# LargeDummyDevice register map
File version: 1.0
Registers are 32-bit, read-write, no defined reset value unless marked. A register's access mark holds for its fields unless they carry their own. Offsets are from the block's base; [hi:lo] are bit positions.

## PERIPHERAL_32
Base 0x4001F000
0x04 REG_1 — Register 1
  [9:5] FIELD_1, [9:5] FIELD_3, [3] FIELD_2
0x08 REG_2 — Register 2
  [28] FIELD_18, [31:27] FIELD_6, [31:27] FIELD_16, [26] FIELD_4, [26:22] FIELD_9, [23:21] FIELD_3, [24:21] FIELD_7, [22:21] FIELD_10, [24:21] FIELD_14, [16:14] FIELD_8, [15:13] FIELD_2, [13] FIELD_11, [8] FIELD_15, [8:7] FIELD_1, [7] FIELD_17, [5] FIELD_13, [6:4] FIELD_5, [2] FIELD_12
0x0C REG_3 — Register 3
  [28:26] FIELD_8, [28:24] FIELD_3, [19:15] FIELD_9, [17:14] FIELD_1, [10] FIELD_5, [10:9] FIELD_7, [7] FIELD_4, [10:6] FIELD_10, [7:4] FIELD_2, [1] FIELD_6
0x10 REG_4 — Register 4
  [33:30] FIELD_14, [32:28] FIELD_1, [29:26] FIELD_11, [27:25] FIELD_17, [25:24] FIELD_7, [27:24] FIELD_13, [25:22] FIELD_6, [17:13] FIELD_9, [14:12] FIELD_10, [12:10] FIELD_5, [10:8] FIELD_16, [7] FIELD_4, [10:7] FIELD_12, [3:2] FIELD_15, [4:0] FIELD_2, [3:0] FIELD_3, [2:0] FIELD_8
0x14 REG_5 — Register 5
  [31:27] FIELD_2, [24:21] FIELD_5, [17:13] FIELD_4, [13:10] FIELD_6, [8:7] FIELD_1, [5:1] FIELD_3
0x18 REG_6 — Register 6
  [33:31] FIELD_1, [31] FIELD_12, [30:29] FIELD_14, [29:28] FIELD_16, [27] FIELD_5, [27:26] FIELD_2, [27:25] FIELD_18, [25:21] FIELD_8, [23:21] FIELD_9, [23:20] FIELD_15, [15:14] FIELD_6, [15:11] FIELD_4, [13:10] FIELD_7, [10] FIELD_19, [10:9] FIELD_13, [10:9] FIELD_20, [8] FIELD_3, [11:8] FIELD_10, [7:6] FIELD_17, [6] FIELD_21, [7:4] FIELD_11
0x1C REG_7 — Register 7
  [31:27] FIELD_5, [18:14] FIELD_4, [14:13] FIELD_3, [13:11] FIELD_1, [12:10] FIELD_2, [8:6] FIELD_6
0x20 REG_8 — Register 8
  [31] FIELD_2, [29] FIELD_7, [26] FIELD_4, [27:24] FIELD_1, [20:16] FIELD_5, [10:8] FIELD_6, [9:6] FIELD_8, [5] FIELD_3
0x24 REG_9 — Register 9
  [29:28] FIELD_6, [30:28] FIELD_11, [31:27] FIELD_2, [27] FIELD_10, [26:25] FIELD_26, [27:24] FIELD_14, [27:24] FIELD_22, [25:23] FIELD_7, [27:23] FIELD_27, [24:21] FIELD_4, [21] FIELD_12, [24:21] FIELD_23, [22:20] FIELD_5, [24:20] FIELD_24, [23:19] FIELD_3, [23:19] FIELD_15, [20:18] FIELD_1, [12] FIELD_16, [13:12] FIELD_25, [14:10] FIELD_21, [11:8] FIELD_9, [6:5] FIELD_20, [5:3] FIELD_13, [4:2] FIELD_18, [4:2] FIELD_19, [3:0] FIELD_8, [1:0] FIELD_17
0x28 REG_10 — Register 10
  [33:31] FIELD_5, [28] FIELD_7, [28:27] FIELD_6, [26:22] FIELD_2, [21] FIELD_4, [23:20] FIELD_1, [15:12] FIELD_3
0x2C REG_11 — Register 11
  [25:22] FIELD_4, [23:20] FIELD_1, [15:14] FIELD_3, [5:1] FIELD_2
0x30 REG_12 — Register 12
  [30:29] FIELD_1, [30:26] FIELD_5, [30:26] FIELD_7, [26:23] FIELD_8, [21] FIELD_13, [22:19] FIELD_2, [22:19] FIELD_14, [14:13] FIELD_6, [15:12] FIELD_16, [9] FIELD_11, [9:5] FIELD_10, [9:5] FIELD_12, [4] FIELD_4, [5:3] FIELD_3, [3:0] FIELD_9, [2:0] FIELD_15, [3:0] FIELD_17
0x34 REG_13 — Register 13
  [35:31] FIELD_6, [33:31] FIELD_10, [30] FIELD_2, [29:27] FIELD_1, [29:26] FIELD_5, [21:20] FIELD_7, [19] FIELD_9, [21:18] FIELD_8, [20:17] FIELD_13, [16:14] FIELD_11, [13:9] FIELD_12, [8:5] FIELD_3, [3] FIELD_14, [2:1] FIELD_4
0x38 REG_14 — Register 14
  [32:31] FIELD_8, [26] FIELD_16, [27:25] FIELD_4, [29:25] FIELD_14, [25:23] FIELD_9, [21] FIELD_10, [21:20] FIELD_7, [24:20] FIELD_11, [19] FIELD_13, [18] FIELD_18, [18:16] FIELD_5, [20:16] FIELD_19, [16:14] FIELD_2, [13] FIELD_1, [11] FIELD_15, [13:9] FIELD_6, [11:9] FIELD_17, [9:8] FIELD_21, [7:6] FIELD_20, [8:5] FIELD_3, [8:4] FIELD_22, [3:0] FIELD_12
0x3C REG_15 — Register 15
  [32:31] FIELD_21, [32:29] FIELD_17, [31:28] FIELD_22, [29:28] FIELD_23, [29:27] FIELD_2, [27] FIELD_15, [20:18] FIELD_9, [19:18] FIELD_10, [17] FIELD_5, [17:16] FIELD_7, [20:16] FIELD_11, [18:16] FIELD_16, [15] FIELD_12, [14:10] FIELD_20, [11:9] FIELD_14, [8] FIELD_1, [9:7] FIELD_18, [10:7] FIELD_25, [10:6] FIELD_19, [7:5] FIELD_3, [9:5] FIELD_4, [6:5] FIELD_8, [5:4] FIELD_13, [1:0] FIELD_6, [2:0] FIELD_24, [4:0] FIELD_26
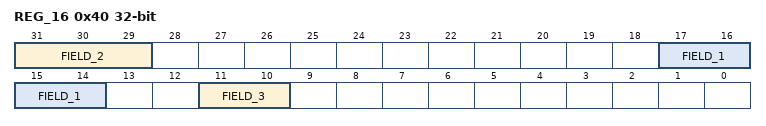
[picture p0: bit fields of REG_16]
0x40 REG_16 — Register 16
  [31:29] FIELD_2, [17:14] FIELD_1, [11:10] FIELD_3
0x44 REG_17 — Register 17
  [31:29] FIELD_5, [32:29] FIELD_10, [31:29] FIELD_13, [27] FIELD_7, [30:27] FIELD_17, [24] FIELD_4, [20] FIELD_2, [23:19] FIELD_16, [19:18] FIELD_12, [16] FIELD_22, [19:16] FIELD_24, [18:15] FIELD_18, [11:10] FIELD_6, [10] FIELD_23, [8] FIELD_8, [10:8] FIELD_11, [9:7] FIELD_14, [7] FIELD_19, [6] FIELD_1, [5:4] FIELD_3, [7:4] FIELD_20, [4:3] FIELD_9, [5:1] FIELD_21, [0] FIELD_15
0x48 REG_18 — Register 18
  [34:31] FIELD_4, [34:31] FIELD_15, [34:31] FIELD_17, [29:28] FIELD_8, [26:24] FIELD_2, [26:24] FIELD_13, [23:22] FIELD_12, [22:21] FIELD_19, [22:20] FIELD_3, [23:20] FIELD_6, [18] FIELD_11, [20:17] FIELD_5, [17:16] FIELD_1, [15:14] FIELD_16, [13:11] FIELD_9, [8] FIELD_7, [11:8] FIELD_10, [8] FIELD_20, [7:6] FIELD_14, [2] FIELD_18
0x4C REG_19 — Register 19
  [29:26] FIELD_4, [29:26] FIELD_11, [27:25] FIELD_9, [23:20] FIELD_1, [20:19] FIELD_10, [19:17] FIELD_2, [15] FIELD_8, [13:12] FIELD_12, [13:9] FIELD_3, [8] FIELD_6, [7] FIELD_7, [5:4] FIELD_5
0x50 REG_20 — Register 20
  [34:30] FIELD_7, [32:28] FIELD_9, [31:27] FIELD_2, [29:27] FIELD_5, [29:27] FIELD_20, [26:23] FIELD_16, [21] FIELD_17, [23:20] FIELD_10, [23:19] FIELD_11, [20:18] FIELD_6, [21:18] FIELD_13, [19:17] FIELD_21, [17:14] FIELD_3, [15:14] FIELD_8, [17:14] FIELD_19, [16:13] FIELD_1, [10:9] FIELD_15, [9:8] FIELD_12, [7:6] FIELD_4, [9:5] FIELD_18, [3:2] FIELD_14
0x54 REG_21 — Register 21
  [18:14] FIELD_1
0x58 REG_22 — Register 22
  [30:29] FIELD_8, [31:28] FIELD_5, [30:28] FIELD_9, [27:26] FIELD_7, [28:25] FIELD_6, [28:25] FIELD_10, [23] FIELD_4, [18:17] FIELD_11, [15:11] FIELD_1, [9] FIELD_2, [3:2] FIELD_3
0x5C REG_23 — Register 23
  [32:31] FIELD_12, [30:28] FIELD_16, [26:24] FIELD_11, [25:24] FIELD_14, [28:24] FIELD_22, [25:23] FIELD_26, [24:23] FIELD_29, [24:22] FIELD_24, [25:21] FIELD_9, [23:20] FIELD_1, [21:20] FIELD_4, [22:20] FIELD_8, [19:16] FIELD_18, [19:15] FIELD_2, [16:15] FIELD_5, [16:15] FIELD_15, [16:15] FIELD_21, [14:13] FIELD_13, [16:12] FIELD_19, [8] FIELD_10, [12:8] FIELD_27, [11:7] FIELD_7, [8:7] FIELD_17, [9:7] FIELD_20, [8:7] FIELD_25, [10:7] FIELD_28, [4] FIELD_3, [5:4] FIELD_6, [4] FIELD_30, [1] FIELD_23
0x60 REG_24 — Register 24
  [33:31] FIELD_2, [32:31] FIELD_8, [17] FIELD_7, [15:11] FIELD_6, [9] FIELD_3, [6] FIELD_4, [3] FIELD_5, [4:2] FIELD_1
0x64 REG_25 — Register 25
  [34:31] FIELD_13, [27:23] FIELD_14, [22:21] FIELD_12, [24:20] FIELD_4, [22:19] FIELD_5, [22:19] FIELD_9, [21:18] FIELD_2, [22:18] FIELD_15, [20:16] FIELD_1, [20:16] FIELD_7, [15] FIELD_3, [13:12] FIELD_10, [8] FIELD_11, [9:8] FIELD_16, [8] FIELD_22, [11:7] FIELD_17, [9:7] FIELD_19, [8:6] FIELD_21, [7:4] FIELD_8, [5:4] FIELD_18, [8:4] FIELD_20, [8:4] FIELD_23, [5:3] FIELD_6
0x68 REG_26 — Register 26
  [31] FIELD_6, [31] FIELD_14, [28] FIELD_9, [29:25] FIELD_15, [27:24] FIELD_8, [28:24] FIELD_13, [27:23] FIELD_12, [23:20] FIELD_3, [21:18] FIELD_11, [20:16] FIELD_1, [14:12] FIELD_7, [15:12] FIELD_21, [13:11] FIELD_10, [14:11] FIELD_18, [15:11] FIELD_19, [11:10] FIELD_5, [7] FIELD_2, [10:7] FIELD_16, [5:4] FIELD_22, [3] FIELD_20, [3:2] FIELD_4, [5:1] FIELD_17
0x6C REG_27 — Register 27
  [23] FIELD_2, [25:22] FIELD_7, [23:21] FIELD_4, [21:20] FIELD_8, [23:19] FIELD_6, [19:16] FIELD_3, [17:13] FIELD_9, [11:8] FIELD_1, [6:5] FIELD_5
0x70 REG_28 — Register 28
  [31:29] FIELD_5, [28:25] FIELD_10, [24:20] FIELD_8, [21:19] FIELD_4, [17:14] FIELD_2, [14:12] FIELD_6, [11:10] FIELD_9, [8] FIELD_11, [11:7] FIELD_1, [4] FIELD_3, [2:1] FIELD_7
0x74 REG_29 — Register 29
  [31:30] FIELD_1, [32:29] FIELD_19, [32:28] FIELD_14, [28] FIELD_17, [28:26] FIELD_4, [29:25] FIELD_22, [24:23] FIELD_23, [24:21] FIELD_10, [23:20] FIELD_26, [20:16] FIELD_18, [18:15] FIELD_12, [19:15] FIELD_27, [17:14] FIELD_3, [14:13] FIELD_8, [14:13] FIELD_20, [13] FIELD_24, [13:12] FIELD_13, [13:10] FIELD_7, [13:9] FIELD_11, [10:8] FIELD_15, [12:8] FIELD_25, [7:6] FIELD_16, [6:5] FIELD_2, [8:5] FIELD_21, [5:2] FIELD_5, [2:0] FIELD_6, [3:0] FIELD_9
0x78 REG_30 — Register 30
  [29:28] FIELD_3, [24:20] FIELD_5, [19] FIELD_2, [20:19] FIELD_4, [23:19] FIELD_7, [12:8] FIELD_6, [4:2] FIELD_1
0x7C REG_31 — Register 31
  [4] FIELD_1
0x80 REG_32 — Register 32
  [30] FIELD_25, [31:29] FIELD_11, [26] FIELD_7, [28:26] FIELD_13, [26] FIELD_14, [29:26] FIELD_16, [23] FIELD_23, [26:23] FIELD_27, [24:22] FIELD_2, [23:20] FIELD_5, [23:20] FIELD_22, [22:20] FIELD_24, [21:18] FIELD_19, [18:14] FIELD_6, [12] FIELD_8, [14:11] FIELD_28, [10:8] FIELD_3, [10:8] FIELD_18, [9:7] FIELD_20, [6] FIELD_1, [8:6] FIELD_21, [4] FIELD_26, [5:3] FIELD_4, [4:3] FIELD_9, [7:3] FIELD_15, [5:2] FIELD_10, [6:2] FIELD_12, [2:1] FIELD_17
0x84 REG_33 — Register 33
  [32:31] FIELD_4, [33:31] FIELD_8, [30:29] FIELD_15, [29:28] FIELD_10, [30:28] FIELD_17, [28] FIELD_28, [27:26] FIELD_27, [29:26] FIELD_29, [26:22] FIELD_19, [21] FIELD_2, [22:20] FIELD_5, [23:20] FIELD_13, [20:19] FIELD_7, [23:19] FIELD_12, [21:17] FIELD_9, [21:17] FIELD_24, [17] FIELD_30, [15:14] FIELD_6, [16:13] FIELD_16, [16:12] FIELD_25, [12:11] FIELD_3, [12:8] FIELD_22, [11:8] FIELD_23, [8:7] FIELD_21, [7:3] FIELD_18, [2] FIELD_11, [6:2] FIELD_26, [0] FIELD_1, [2:0] FIELD_14, [0] FIELD_20
0x88 REG_34 — Register 34
  [35:31] FIELD_1, [33:31] FIELD_17, [35:31] FIELD_18, [32:29] FIELD_15, [27:26] FIELD_16, [30:26] FIELD_20, [24:21] FIELD_4, [23:21] FIELD_19, [25:21] FIELD_27, [23:19] FIELD_25, [18:17] FIELD_3, [19:17] FIELD_7, [17:16] FIELD_2, [19:15] FIELD_24, [16:15] FIELD_28, [16:14] FIELD_8, [16:13] FIELD_22, [16:12] FIELD_5, [11] FIELD_21, [9:8] FIELD_9, [12:8] FIELD_23, [8:7] FIELD_12, [10:6] FIELD_10, [5:4] FIELD_13, [7:4] FIELD_29, [4:3] FIELD_26, [3] FIELD_30, [4:2] FIELD_11, [2] FIELD_14, [3:0] FIELD_6
0x8C REG_35 — Register 35
  [30:28] FIELD_10, [23:21] FIELD_9, [19] FIELD_8, [16:15] FIELD_2, [14:12] FIELD_1, [14:12] FIELD_4, [15:11] FIELD_5, [13:10] FIELD_7, [10:8] FIELD_6, [8:7] FIELD_3
0x90 REG_36 — Register 36
  [31:29] FIELD_2, [29:28] FIELD_16, [29:28] FIELD_19, [25:21] FIELD_20, [19] FIELD_4, [22:19] FIELD_6, [18] FIELD_22, [17:13] FIELD_1, [16:13] FIELD_10, [14:13] FIELD_17, [12:10] FIELD_7, [11:10] FIELD_9, [10] FIELD_14, [8] FIELD_15, [8:7] FIELD_5, [9:6] FIELD_8, [8:6] FIELD_21, [6:3] FIELD_12, [6:3] FIELD_13, [6:2] FIELD_23, [4:0] FIELD_3, [4:0] FIELD_11, [3:0] FIELD_18, [4:0] FIELD_24
0x94 REG_37 — Register 37
  [34:30] FIELD_12, [30:29] FIELD_10, [27] FIELD_6, [24:22] FIELD_1, [24:22] FIELD_16, [21:19] FIELD_4, [23:19] FIELD_7, [19:16] FIELD_9, [18:15] FIELD_8, [10:9] FIELD_2, [11:9] FIELD_3, [8:6] FIELD_13, [7:5] FIELD_18, [2] FIELD_14, [2:1] FIELD_15, [4:1] FIELD_17, [0] FIELD_5, [3:0] FIELD_11
0x98 REG_38 — Register 38
  [32:30] FIELD_8, [30] FIELD_13, [32:29] FIELD_2, [31:28] FIELD_1, [28:26] FIELD_19, [28:24] FIELD_10, [25:24] FIELD_20, [27:23] FIELD_18, [24:21] FIELD_16, [20:18] FIELD_3, [22:18] FIELD_5, [17:16] FIELD_7, [16:15] FIELD_11, [12:10] FIELD_15, [11:7] FIELD_9, [9:7] FIELD_12, [9:6] FIELD_6, [8:4] FIELD_4, [6:2] FIELD_14, [0] FIELD_17
0x9C REG_39 — Register 39
  [34:31] FIELD_11, [31] FIELD_16, [31:29] FIELD_3, [29] FIELD_23, [30:28] FIELD_17, [28:27] FIELD_13, [29:27] FIELD_14, [29:26] FIELD_19, [23] FIELD_6, [25:23] FIELD_21, [22:21] FIELD_4, [22:21] FIELD_8, [23:20] FIELD_12, [20:19] FIELD_20, [19:16] FIELD_1, [16] FIELD_5, [18:16] FIELD_7, [19:16] FIELD_10, [17:16] FIELD_15, [13] FIELD_28, [6] FIELD_9, [7:4] FIELD_22, [3:2] FIELD_2, [6:2] FIELD_18, [3:1] FIELD_24, [5:1] FIELD_25, [3:0] FIELD_26, [1:0] FIELD_27
0xA0 REG_40 — Register 40
  [35:31] FIELD_1, [26] FIELD_5, [22:19] FIELD_2, [23:19] FIELD_6, [16:13] FIELD_7, [13:9] FIELD_3, [4:2] FIELD_4
0xA4 REG_41 — Register 41
  [6:5] FIELD_1
0xA8 REG_42 — Register 42
  [20:17] FIELD_1, [14:11] FIELD_2, [15:11] FIELD_3
0xAC REG_43 — Register 43
  [31] FIELD_19, [30] FIELD_2, [32:30] FIELD_17, [30:28] FIELD_5, [28] FIELD_15, [28:25] FIELD_23, [18:17] FIELD_14, [17] FIELD_21, [18:15] FIELD_10, [18:15] FIELD_22, [16:14] FIELD_20, [16:14] FIELD_24, [16:13] FIELD_9, [15:11] FIELD_18, [10] FIELD_3, [13:9] FIELD_1, [10:9] FIELD_4, [12:9] FIELD_6, [13:9] FIELD_12, [7] FIELD_7, [10:7] FIELD_13, [10:6] FIELD_25, [6:4] FIELD_8, [4:1] FIELD_11, [2:0] FIELD_16
